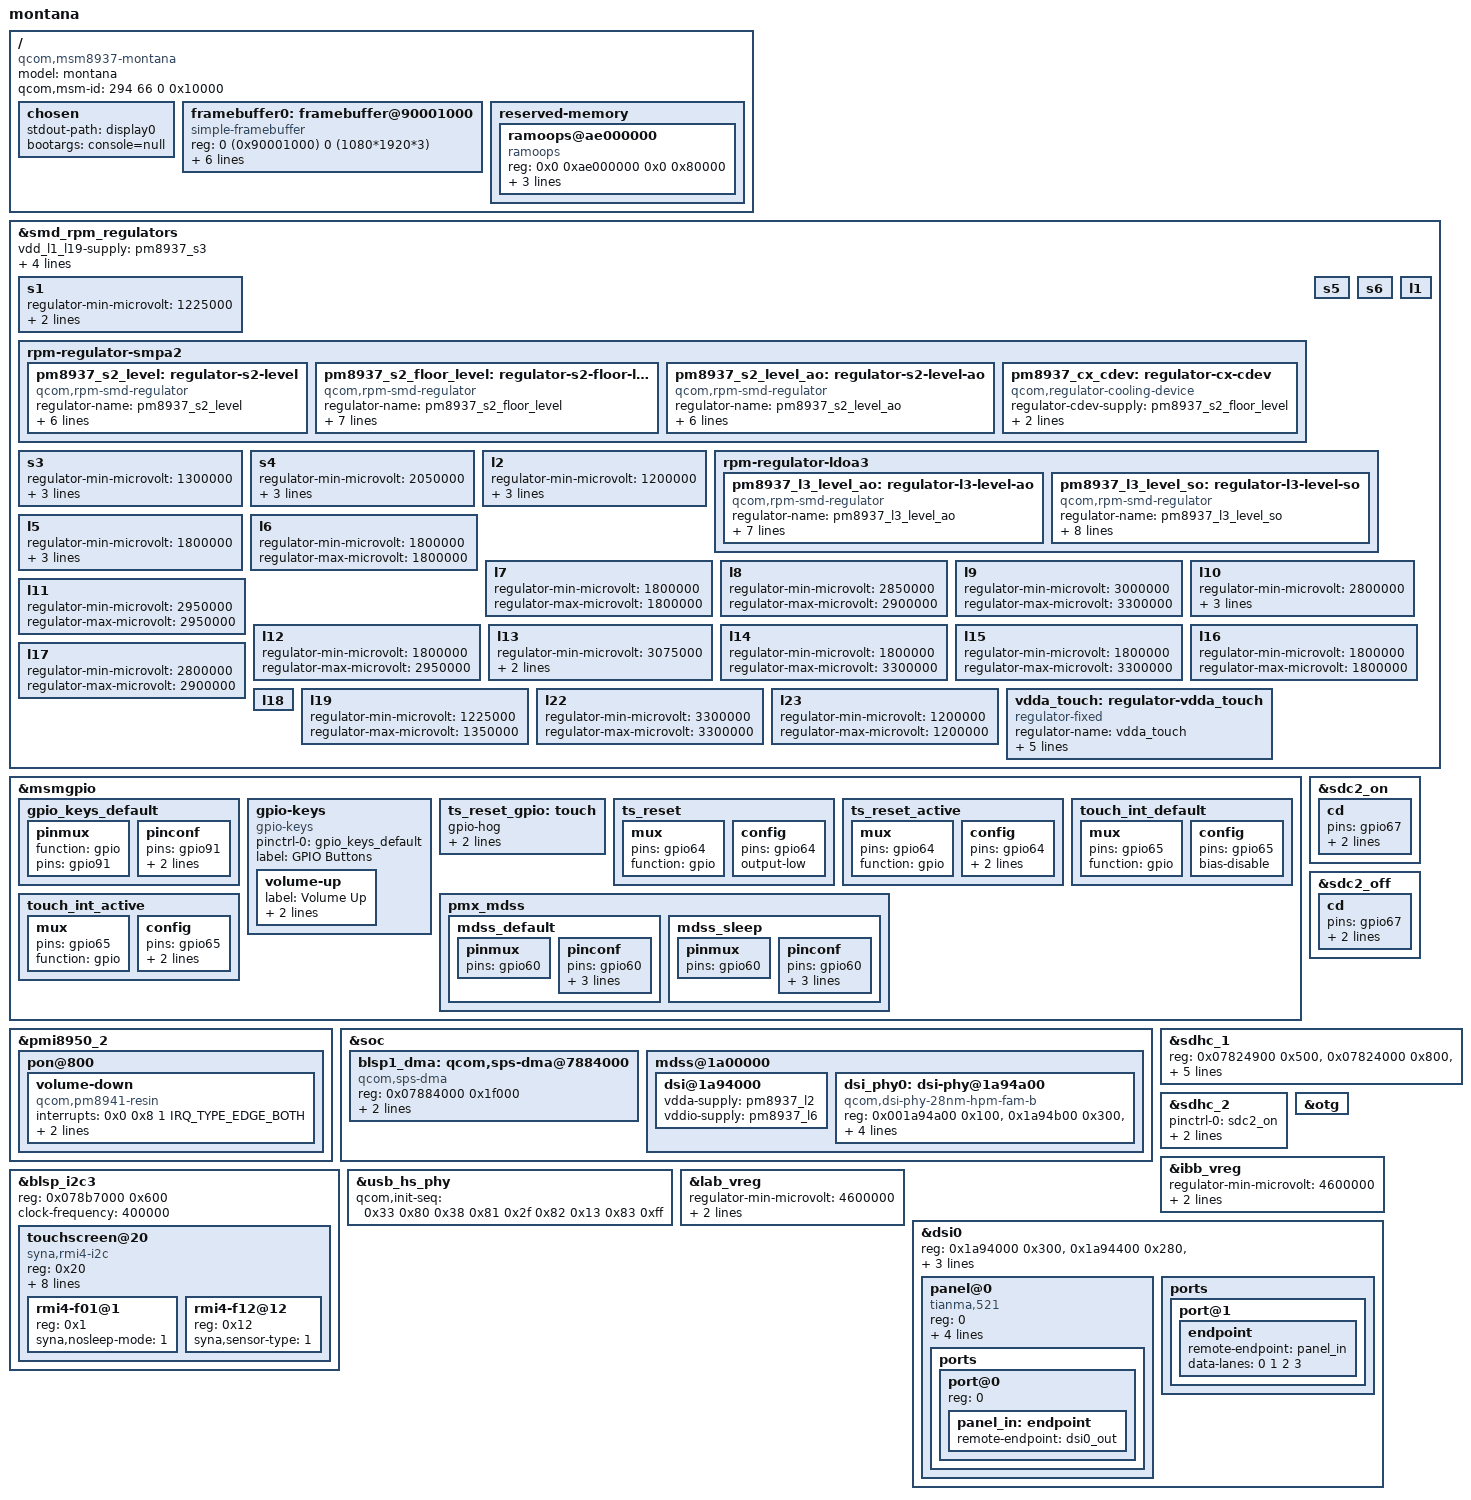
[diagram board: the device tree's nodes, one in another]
// SPDX-License-Identifier: GPL-2.0

/dts-v1/;

#include "msm8937.dtsi"
#include "msm8937-pmi8950.dtsi"
#include <dt-bindings/regulator/qcom,rpm-smd-regulator.h>

/ {
	model = "montana";
	compatible = "qcom,msm8937-montana", "qcom,msm8937-moto", "qcom,msm8937";
	qcom,msm-id = <294 66 0 0x10000>;
};

/ {
	chosen {
		stdout-path = "display0";
		bootargs = "console=null";
	};

	framebuffer0: framebuffer@90001000 {
		compatible = "simple-framebuffer";
		reg = <0 (0x90001000) 0 (1080*1920*3)>;
		width = <1080>;
		height = <1920>;
		stride = <(1080 * 3)>;
		format = "r8g8b8";
		status = "okay";
		display = &mdss;
		power-domains = <&gcc MDSS_GDSC>;
	};
};

/ {
	reserved-memory {
		ranges;

		ramoops@ae000000 {
			compatible = "ramoops";
			reg = <0x0 0xae000000 0x0 0x80000>;
			console-size = <0x40000>;
			pmsg-size = <0x40000>;
			record-size = <0x3f800>;
		};
	};
};

&smd_rpm_regulators {
	/*vdd_s1-supply = <&dummy_reg0>;
	vdd_s2-supply = <&dummy_reg0>;
	vdd_s3-supply = <&dummy_reg0>;
	vdd_s4-supply = <&dummy_reg0>;
	vdd_s5-supply = <&dummy_reg0>;
	vdd_s6-supply = <&dummy_reg0>;*/
	vdd_l1_l19-supply = <&pm8937_s3>;
	vdd_l2_l23-supply = <&pm8937_s3>;
	vdd_l3-supply = <&pm8937_s3>;
	vdd_l4_l5_l6_l7_l16-supply = <&pm8937_s4>;
	vdd_l20_l21-supply = <&pm8937_s4>;
	//vdd_l8_l11_l12_l17_l22-supply = <&dummy_reg0>;
	//vdd_l9_l10_l13_l14_l15_l18-supply = <&dummy_reg0>;

	/* MSM modem */
	s1 {
		//regulator-min-microvolt = <1000000>;
		regulator-min-microvolt = <1225000>;
		regulator-max-microvolt = <1225000>;
		regulator-always-on; // XXX
	};

	/* VDD_CX supply */
	rpm-regulator-smpa2 {
		status = "okay";
		pm8937_s2_level: regulator-s2-level {
			compatible = "qcom,rpm-smd-regulator";
			regulator-name = "pm8937_s2_level";
			qcom,set = <3>;
			regulator-min-microvolt =
				<RPM_SMD_REGULATOR_LEVEL_RETENTION>;
			regulator-max-microvolt =
				<RPM_SMD_REGULATOR_LEVEL_BINNING>;
			qcom,use-voltage-level;
		};

		pm8937_s2_floor_level: regulator-s2-floor-level {
			compatible = "qcom,rpm-smd-regulator";
			regulator-name = "pm8937_s2_floor_level";
			qcom,set = <3>;
			regulator-min-microvolt =
				<RPM_SMD_REGULATOR_LEVEL_RETENTION>;
			regulator-max-microvolt =
				<RPM_SMD_REGULATOR_LEVEL_BINNING>;
			qcom,use-voltage-floor-level;
			qcom,always-send-voltage;
		};

		pm8937_s2_level_ao: regulator-s2-level-ao {
			compatible = "qcom,rpm-smd-regulator";
			regulator-name = "pm8937_s2_level_ao";
			qcom,set = <1>;
			regulator-min-microvolt =
				<RPM_SMD_REGULATOR_LEVEL_RETENTION>;
			regulator-max-microvolt =
				<RPM_SMD_REGULATOR_LEVEL_BINNING>;
			qcom,use-voltage-level;
		};

		pm8937_cx_cdev: regulator-cx-cdev {
			compatible = "qcom,regulator-cooling-device";
			regulator-cdev-supply = <&pm8937_s2_floor_level>;
			regulator-levels = <RPM_SMD_REGULATOR_LEVEL_NOM_PLUS
					RPM_SMD_REGULATOR_LEVEL_RETENTION>;
			#cooling-cells = <2>;
		};
	};


	s3 {
		regulator-min-microvolt = <1300000>;
		regulator-max-microvolt = <1300000>;
		regulator-boot-on;
		regulator-always-on;
	};

	s4 {
		regulator-min-microvolt = <2050000>;
		regulator-max-microvolt = <2050000>;
		regulator-boot-on;
		regulator-always-on;
	};

	/* MSM applications processor */
	s5 {
	};

	/* MSM applications processor */
	s6 {
	};

	/* RFICs */
	l1 {
	};

	/* LPDDR2/LPDDR3, MIPI CSI, and DSI */
	l2 {
		regulator-min-microvolt = <1200000>;
		regulator-max-microvolt = <1200000>;
		regulator-boot-on;
		regulator-always-on;
	};

	/* VDD_MX supply */
	rpm-regulator-ldoa3 {
		status = "okay";
		pm8937_l3_level_ao: regulator-l3-level-ao {
			compatible = "qcom,rpm-smd-regulator";
			regulator-name = "pm8937_l3_level_ao";
			qcom,set = <1>;
			regulator-min-microvolt =
				<RPM_SMD_REGULATOR_LEVEL_RETENTION>;
			regulator-max-microvolt =
				<RPM_SMD_REGULATOR_LEVEL_TURBO>;
			qcom,use-voltage-level;
			qcom,always-send-voltage;
		};

		pm8937_l3_level_so: regulator-l3-level-so {
			compatible = "qcom,rpm-smd-regulator";
			regulator-name = "pm8937_l3_level_so";
			qcom,set = <2>;
			regulator-min-microvolt =
				<RPM_SMD_REGULATOR_LEVEL_RETENTION>;
			regulator-max-microvolt =
				<RPM_SMD_REGULATOR_LEVEL_TURBO>;
			qcom,init-voltage-level =
				<RPM_SMD_REGULATOR_LEVEL_RETENTION>;
			qcom,use-voltage-level;
		};
	};

	/* Most digital I/Os, MSM pad groups 3 and 7, LPDDR, and eMMC */
	l5 {
		regulator-min-microvolt = <1800000>;
		regulator-max-microvolt = <1800000>;
		regulator-boot-on;
		regulator-always-on;
	};

	/* MSM DSI PLL and OTP, camera, touchscreen, display, and sensors */
	l6 {
		regulator-min-microvolt = <1800000>;
		regulator-max-microvolt = <1800000>;
	};

	/* MSM analog and PLLs, WCN XO, and PM baseband clock driver */
	l7 {
		regulator-min-microvolt = <1800000>;
		regulator-max-microvolt = <1800000>;
	};

	/* eMMC */
	l8 {
		regulator-min-microvolt = <2850000>;
		regulator-max-microvolt = <2900000>;
	};

	/* WCN */
	l9 {
		regulator-min-microvolt = <3000000>;
		regulator-max-microvolt = <3300000>;
	};

	/* Sensors */
	l10 {
		regulator-min-microvolt = <2800000>;
		regulator-max-microvolt = <3000000>;
		regulator-always-on; // XXX touch
		regulator-boot-on;
	};

	/* Micro SD */
	l11 {
		regulator-min-microvolt = <2950000>;
		regulator-max-microvolt = <2950000>;
	};

	/* MSM pad group 2 and SDC2 */
	l12 {
		regulator-min-microvolt = <1800000>;
		regulator-max-microvolt = <2950000>;
	};

	/* MSM USB and audio */
	l13 {
		regulator-min-microvolt = <3075000>;
		regulator-max-microvolt = <3075000>;
		regulator-always-on; // XXX audio (micbias+)
	};

	/* MSM pad group 5, dual-voltage UIM1, and NFC */
	l14 {
		regulator-min-microvolt = <1800000>;
		regulator-max-microvolt = <3300000>;
	};

	/* MSM pad group 6 and dual-voltage UIM2 */
	l15 {
		regulator-min-microvolt = <1800000>;
		regulator-max-microvolt = <3300000>;
	};

	/* PMIC HKADC */
	l16 {
		regulator-min-microvolt = <1800000>;
		regulator-max-microvolt = <1800000>;
	};

	/* Camera, display, and touchscreen */
	l17 {
		regulator-min-microvolt = <2800000>;
		regulator-max-microvolt = <2900000>;
	};

	/* QTI RF front-end */
	l18 {
	};

	/* MSM analog, WCN, and WGR */
	l19 {
		regulator-min-microvolt = <1225000>;
		regulator-max-microvolt = <1350000>;
	};

	/* Camera - analog */
	l22 {
		regulator-min-microvolt = <3300000>;
		regulator-max-microvolt = <3300000>;
	};

	/* Camera - digital */
	l23 {
		regulator-min-microvolt = <1200000>;
		regulator-max-microvolt = <1200000>;
	};
	
	vdda_touch: regulator-vdda_touch {
		compatible = "regulator-fixed";
		regulator-name = "vdda_touch";
		gpio = <&msmgpio 59 0>;
		startup-delay-us = <300>;
		enable-active-high;
		regulator-always-on;
		regulator-boot-on;
	};
};

&msmgpio {
	gpio_keys_default: gpio_keys_default {
		pinmux {
			function = "gpio";
			pins = "gpio91";
		};
		pinconf {
			pins = "gpio91";
			drive-strength = <2>;
			bias-pull-up;
		};
	};

	gpio-keys {
		compatible = "gpio-keys";

		pinctrl-names = "default";
		pinctrl-0 = <&gpio_keys_default>;

		label = "GPIO Buttons";

		volume-up {
			label = "Volume Up";
			gpios = <&msmgpio 91 GPIO_ACTIVE_LOW>;
			linux,code = <KEY_UP>;
		};
	};

	ts_reset_gpio: touch {
		gpio-hog;
		gpios = <64 GPIO_ACTIVE_HIGH>;
		output-high;
	};

	ts_reset: ts_reset {
		mux {
			pins = "gpio64";
			function = "gpio";
		};
		config {
			pins = "gpio64";
			output-low;
		};
	};

	ts_reset_active: ts_reset_active {
		mux {
			pins = "gpio64";
			function = "gpio";
		};
		config {
			pins = "gpio64";
			drive-strength = <2>;
			bias-pull-up;
		};
	};

	touch_int_default: touch_int_default {
		mux {
			pins = "gpio65";
			function = "gpio";
		};
		config {
			pins = "gpio65";
			bias-disable;
		};
	};

	touch_int_active: touch_int_active {
		mux {
			pins = "gpio65";
			function = "gpio";
		};
		config {
			pins = "gpio65";
			drive-strength = <2>;
			bias-pull-up;
		};
	};
	
	pmx_mdss {
		mdss_default: mdss_default {
			pinmux {
				pins = "gpio60";
			};

			pinconf {
				pins = "gpio60";
				drive-strength = <8>; /* 8 mA */
				bias-disable = <0>; /* no pull */
				output-high;
			};
		};

		mdss_sleep: mdss_sleep {
			pinmux {
				pins = "gpio60";
			};

			pinconf {
				pins = "gpio60";
				drive-strength = <2>; /* 2 mA */
				bias-pull-down; /* pull down */
				input-enable;
			};
		};
	};
};

&sdc2_on {
	cd {
		pins = "gpio67";
		drive-strength = <2>;
		bias-disable;
	};

};

&sdc2_off {
	cd {
		pins = "gpio67";
		drive-strength = <2>;
		bias-disable;
	};
};

&pmi8950_2 {
	pon@800 {
		volume-down {
			compatible = "qcom,pm8941-resin";
			interrupts = <0x0 0x8 1 IRQ_TYPE_EDGE_BOTH>;
			bias-pull-up;
			//linux,code = <KEY_VOLUMEDOWN>;
			linux,code = <KEY_DOWN>;
		};
	};
};

&soc {
	blsp1_dma: qcom,sps-dma@7884000 {
		#dma-cells = <4>;
		compatible = "qcom,sps-dma";
		reg = <0x07884000 0x1f000>;
		interrupts = <GIC_SPI 238 IRQ_TYPE_LEVEL_HIGH>;
		qcom,summing-threshold = <10>;
	};

	mdss@1a00000 {
		dsi@1a94000 {
			#address-cells = <1>;
			#size-cells = <0>;

			vdda-supply = <&pm8937_l2>;
			vddio-supply = <&pm8937_l6>;
		};

		/delete-node/ dsi-phy@1a94300;

		dsi_phy0: dsi-phy@1a94a00 {
			compatible = "qcom,dsi-phy-28nm-hpm-fam-b";
			
			reg = <0x001a94a00 0x100>,
			      <0x1a94b00 0x300>,
			      <0x1a94300 0x188>;

			reg-names = "dsi_phy",
			            "dsi_phy_lane",
			            "dsi_pll";

			#clock-cells = <1>;
			#phy-cells = <0>;

			clocks = <&gcc GCC_MDSS_AHB_CLK>;
			clock-names = "iface";
			
			vddio-supply = <&pm8937_l6>;
			qcom,dsi-phy-regulator-ldo-mode;
		};
	};
};

&blsp_i2c3 {
	reg = <0x078b7000 0x600>;
	clock-frequency = <400000>;
	status = "okay";

	touchscreen@20 {
		reg = <0x20>;
		compatible = "syna,rmi4-i2c";
		interrupts-parent = <&msmgpio>;
		interrupts-extended = <&msmgpio 65 0x0>;

		#address-cells = <1>;
		#size-cells = <0>;

		vdd-supply = <&pm8937_l10>;
		vio-supply = <&pm8937_l6>;
		gpios = <&msmgpio 65 0>,
		<&msmgpio 64 GPIO_ACTIVE_HIGH>;

		pinctrl-names = "init", "suspend";
		pinctrl-0 = <&ts_reset &touch_int_default>;
		pinctrl-1 = <&ts_reset_active &touch_int_active>;

		syna,reset-delay-ms = <100>;

		rmi4-f01@1 {
			reg = <0x1>;
			syna,nosleep-mode = <1>; // Allow sleeping
		};

		rmi4-f12@12 {
			reg = <0x12>;
			syna,sensor-type = <1>; // Touchscreen
		};
	};
};

&sdhc_1 {
	status = "ok";
	reg = <0x07824900 0x500>, <0x07824000 0x800>, <0x7824e00 0x200>;
	reg-names = "hc_mem", "core_mem", "cmdq_mem";

	mmc-hs200-1_8v;
	mmc-hs400-1_8v;

	pinctrl-names = "default", "sleep";
	pinctrl-0 = <&sdc1_on>;
	pinctrl-1 = <&sdc1_off>;
};

&sdhc_2 {
	status = "ok";

	pinctrl-names = "default", "sleep";
	pinctrl-0 = <&sdc2_on>;
	pinctrl-1 = <&sdc2_off>;

	cd-gpios = <&msmgpio 67 0>;
};

&otg {
	status = "ok";
};

&usb_hs_phy {
	qcom,init-seq = /bits/ 8 <0x33 0x80 0x38 0x81 0x2f 0x82 0x13 0x83 0xff>;
};


&ibb_vreg {
	regulator-min-microvolt = <4600000>;
	regulator-max-microvolt = <5500000>;
	regulator-max-microamp = <1550>;

};

&lab_vreg {
	regulator-min-microvolt = <4600000>;
	regulator-max-microvolt = <5500000>;
	regulator-max-microamp = <800>;

};

&dsi0 {

	reg = <0x1a94000 0x300>,
		<0x1a94400 0x280>,
		<0x1a94b80 0x30>,
		<0x193e000 0x30>;
	reg-names = "dsi_ctrl", "dsi_phy",
	      "dsi_phy_regulator", "mmss_misc_phys";
	
	pinctrl-names = "default", "sleep";
	pinctrl-0 = <&mdss_default>;
	pinctrl-1 = <&mdss_sleep>;

	panel@0 {
		compatible = "tianma,521";
		reg = <0>;

		power-supply = <&pm8937_l17>;
		reset-gpios = <&msmgpio 60 0>;
		
		vsp-supply = <&lab_vreg>;
		vsn-supply = <&ibb_vreg>;

		ports {
			#address-cells = <1>;
			#size-cells = <0>;

			port@0 {
				reg = <0>;
				panel_in: endpoint {
					remote-endpoint = <&dsi0_out>;
				};
			};
		};
	};

	ports {
		port@1 {
			endpoint {
				remote-endpoint = <&panel_in>;
				data-lanes = <0 1 2 3>;
			};
		};
	};
};
